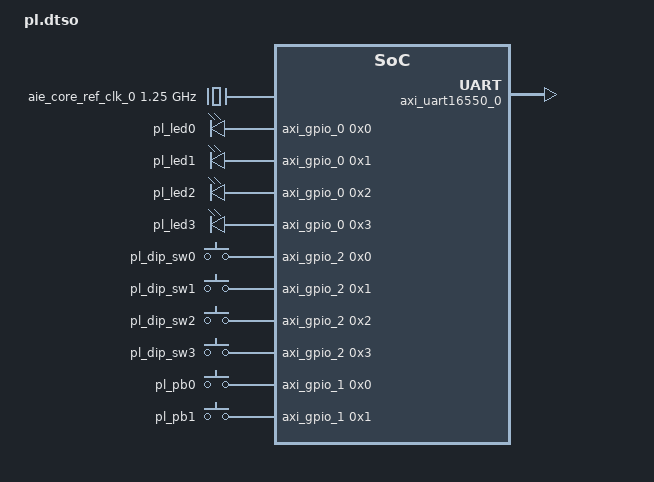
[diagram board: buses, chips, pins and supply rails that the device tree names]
/dts-v1/;
/plugin/;

&fpga {
        firmware-name = "vek280_base_pld.pdi";

        misc_clk_0: misc_clk_0 {
                #clock-cells = <0x0>;
                clock-frequency = <0x5f5e100>;
                compatible = "fixed-clock";
        };
};

&amba {

        axi_gpio_0: gpio@a6010000 {
                gpio-line-names = "pl_led0", "pl_led1", "pl_led2", "pl_led3";
                xlnx,all-inputs = <0x0>;
                xlnx,name = "axi_gpio_0";
                xlnx,tri-default = <0xffffffff>;
                xlnx,use-board-flow;
                clock-names = "s_axi_aclk";
                xlnx,gpio2-width = <0x20>;
                xlnx,dout-default-2 = <0x0>;
                xlnx,edk-iptype = "PERIPHERAL";
                xlnx,gpio2-board-interface = "Custom";
                xlnx,interrupt-present = <0x0>;
                device_type = "gpio";
                gpio-controller;
                xlnx,all-outputs-2 = <0x0>;
                clocks = <&misc_clk_0>;
                xlnx,all-inputs-2 = <0x0>;
                reg = <0x0 0xa6010000 0x0 0x10000>;
                xlnx,tri-default-2 = <0xffffffff>;
                xlnx,ip-name = "axi_gpio";
                xlnx,is-dual = <0x0>;
                xlnx,dout-default = <0x0>;
                xlnx,gpio-width = <0x4>;
                #gpio-cells = <0x2>;
                xlnx,all-outputs = <0x1>;
                compatible = "xlnx,axi-gpio-2.0", "xlnx,xps-gpio-1.00.a";
                xlnx,gpio-board-interface = "gpio_led";
        };

        axi_gpio_1: gpio@a6020000 {
                gpio-line-names = "pl_pb0", "pl_pb1";
                xlnx,all-inputs = <0x1>;
                xlnx,name = "axi_gpio_1";
                xlnx,tri-default = <0xffffffff>;
                xlnx,use-board-flow;
                clock-names = "s_axi_aclk";
                xlnx,gpio2-width = <0x20>;
                xlnx,dout-default-2 = <0x0>;
                xlnx,edk-iptype = "PERIPHERAL";
                xlnx,gpio2-board-interface = "Custom";
                xlnx,interrupt-present = <0x0>;
                device_type = "gpio";
                gpio-controller;
                xlnx,all-outputs-2 = <0x0>;
                clocks = <&misc_clk_0>;
                xlnx,all-inputs-2 = <0x0>;
                reg = <0x0 0xa6020000 0x0 0x10000>;
                xlnx,tri-default-2 = <0xffffffff>;
                xlnx,ip-name = "axi_gpio";
                xlnx,is-dual = <0x0>;
                xlnx,dout-default = <0x0>;
                xlnx,gpio-width = <0x2>;
                #gpio-cells = <0x2>;
                xlnx,all-outputs = <0x0>;
                compatible = "xlnx,axi-gpio-2.0", "xlnx,xps-gpio-1.00.a";
                xlnx,gpio-board-interface = "gpio_pb";
        };

        axi_gpio_2: gpio@a6030000 {
                gpio-line-names = "pl_dip_sw0", "pl_dip_sw1", "pl_dip_sw2", "pl_dip_sw3";
                xlnx,all-inputs = <0x1>;
                xlnx,name = "axi_gpio_2";
                xlnx,tri-default = <0xffffffff>;
                xlnx,use-board-flow;
                clock-names = "s_axi_aclk";
                xlnx,gpio2-width = <0x20>;
                xlnx,dout-default-2 = <0x0>;
                xlnx,edk-iptype = "PERIPHERAL";
                xlnx,gpio2-board-interface = "Custom";
                xlnx,interrupt-present = <0x0>;
                device_type = "gpio";
                gpio-controller;
                xlnx,all-outputs-2 = <0x0>;
                clocks = <&misc_clk_0>;
                xlnx,all-inputs-2 = <0x0>;
                reg = <0x0 0xa6030000 0x0 0x10000>;
                xlnx,tri-default-2 = <0xffffffff>;
                xlnx,ip-name = "axi_gpio";
                xlnx,is-dual = <0x0>;
                xlnx,dout-default = <0x0>;
                xlnx,gpio-width = <0x4>;
                #gpio-cells = <0x2>;
                xlnx,all-outputs = <0x0>;
                compatible = "xlnx,axi-gpio-2.0", "xlnx,xps-gpio-1.00.a";
                xlnx,gpio-board-interface = "gpio_dp";
        };

        ai_engine_0: ai_engine@20000000000 {
                xlnx,aie-site = "AIE_ML";
                xlnx,name = "ai_engine_0";
                xlnx,start-column = <0x0>;
                xlnx,name-si-axi = "S00_AXI";
                xlnx,shim-rows = /bits/ 8 <0x00 0x01>;
                xlnx,core-rows = /bits/ 8 <0x03 0x08>;
                xlnx,num-trig-out = <0x0>;
                xlnx,en-ext-rst = <0x0>;
                xlnx,nsu-dict = "NOC_NSU128_X1Y6 0x20000000000 NOC_NSU128_X2Y6 0x20002000000 NOC_NSU128_X3Y6 0x20008000000 NOC_NSU128_X4Y6 0x2000A000000 NOC_NSU128_X5Y6 0x20018000000 NOC_NSU128_X6Y6 0x20020000000 NOC_NSU128_X7Y6 0x2002C000000 NOC_NSU128_X8Y6 0x20032000000 NOC_NSU128_X9Y6 0x2003E000000 NOC_NSU128_X10Y6 0x20042000000 NOC_NSU128_X11Y6 0x20046000000 NOC_NSU128_X12Y6 0x2004A000000";
                xlnx,num-trig-in = <0x0>;
                power-domains = <&versal_firmware 0x18800000>;
                clock-names = "aclk0";
                xlnx,available-nsu = "NOC_NSU128_X1Y6 0x20000000000 NOC_NSU128_X2Y6 0x20002000000 NOC_NSU128_X3Y6 0x20008000000 NOC_NSU128_X4Y6 0x2000A000000 NOC_NSU128_X5Y6 0x20018000000 NOC_NSU128_X6Y6 0x20020000000 NOC_NSU128_X7Y6 0x2002C000000 NOC_NSU128_X8Y6 0x20032000000 NOC_NSU128_X9Y6 0x2003E000000 NOC_NSU128_X10Y6 0x20042000000 NOC_NSU128_X11Y6 0x20046000000 NOC_NSU128_X12Y6 0x2004A000000";
                xlnx,selected-nsu = <0x0>;
                xlnx,edk-iptype = "PERIPHERAL";
                xlnx,fast-dm-write;
                xlnx,name-si-axis = "S00_AXIS";
                xlnx,clk-names = "aclk0";
                xlnx,aie-core-ref-ctrl-freqmhz = <0x4e2>;
                xlnx,num-column = <0x1>;
                xlnx,name-mi-axi = "M00_AXI";
                xlnx,num-si-axis = <0x0>;
                #address-cells = <0x2>;
                xlnx,partition-enabled = <0x0>;
                xlnx,num-clks = <0x0>;
                ranges;
                xlnx,num-noc-axis-clks = <0x0>;
                clocks = <&aie_core_ref_clk_0>;
                reg = <0x200 0x0 0x1 0x0>;
                xlnx,fast-pm-write;
                xlnx,num-si-axi = <0x1>;
                #size-cells = <0x2>;
                xlnx,ip-name = "ai_engine";
                xlnx,mi-destid-pins;
                xlnx,mem-rows = /bits/ 8 <0x01 0x02>;
                xlnx,name-mi-axis = "M00_AXIS";
                xlnx,aie-gen = [02];
                xlnx,aie-max-freq = <0x4e2>;
                xlnx,en-addr-virtualization = <0x0>;
                xlnx,num-mi-axis = <0x0>;
                xlnx,aie-col-dict = "col00 0x20000000000 col01 0x20002000000 col02 0x20004000000 col03 0x20006000000 col04 0x20008000000 col05 0x2000A000000 col06 0x2000C000000 col07 0x2000E000000 col08 0x20010000000 col09 0x20012000000 col10 0x20014000000 col11 0x20016000000 col12 0x20018000000 col13 0x2001A000000 col14 0x2001C000000 col15 0x2001E000000 col16 0x20020000000 col17 0x20022000000 col18 0x20024000000 col19 0x20026000000 col20 0x20028000000 col21 0x2002A000000 col22 0x2002C000000 col23 0x2002E000000 col24 0x20030000000 col25 0x20032000000 col26 0x20034000000 col27 0x20036000000 col28 0x20038000000 col29 0x2003A000000 col30 0x2003C000000 col31 0x2003E000000 col32 0x20040000000 col33 0x20042000000 col34 0x20044000000 col35 0x20046000000 col36 0x20048000000 col37 0x2004A000000";
                xlnx,aie-ref-clk-freqmhz = <0x1fc9f08>;
                compatible = "xlnx,ai-engine-2.0", "xlnx,ai-engine-v2.0";
                xlnx,num-mi-axi = <0x0>;

                aie_aperture_0: aie_aperture@20000000000 {
                        xlnx,columns = <0x0 0x26>;
                        reg = <0x200 0x0 0x1 0x0>;
                        interrupt-names = "interrupt1", "interrupt2", "interrupt3";
                        #size-cells = <0x2>;
                        xlnx,node-id = <0x18800000>;
                        power-domains = <&versal_firmware 0x18800000>;
                        #address-cells = <0x2>;
                        interrupts = <0x0 0x94 0x4 0x0 0x95 0x4 0x0 0x96 0x4>;
                        interrupt-parent = <&gic>;
                        xlnx,device-name = <0x0>;
                };
        };

        axi_bram_ctrl_0: axi_bram_ctrl_0@a4000000 {
                xlnx,name = "axi_bram_ctrl_0";
                xlnx,s-axi-id-width = <0x1>;
                xlnx,mem-depth = <0x800>;
                xlnx,s-axi-ctrl-data-width = <0x20>;
                xlnx,bram-inst-mode = "EXTERNAL";
                xlnx,bram-addr-width = <0xb>;
                xlnx,data-width = <0x20>;
                clock-names = "s_axi_aclk";
                xlnx,edk-iptype = "PERIPHERAL";
                xlnx,ecc = <0x0>;
                xlnx,single-port-bram = <0x0>;
                xlnx,supports-narrow-burst = <0x0>;
                xlnx,s-axi-supports-narrow-burst = <0x0>;
                xlnx,id-width = <0x0>;
                xlnx,read-latency = <0x1>;
                xlnx,s-axi-ctrl-addr-width = <0x20>;
                clocks = <&misc_clk_0>;
                xlnx,bmg-instance = "EXTERNAL";
                reg = <0x0 0xa4000000 0x0 0x2000>;
                xlnx,ip-name = "axi_bram_ctrl";
                xlnx,fault-inject = <0x0>;
                xlnx,use-ecc = <0x0>;
                xlnx,memory-depth = <0x800>;
                xlnx,rd-cmd-optimization = <0x0>;
                xlnx,ecc-type = <0x0>;
                xlnx,ecc-onoff-reset-value = <0x0>;
                compatible = "xlnx,axi-bram-ctrl-4.1", "xlnx,axi-bram-ctrl";
                xlnx,edk-special = "BRAM_CTRL";
                xlnx,protocol = "AXI4";
        };

        axi_uart16550_0: serial@a6000000 {
                xlnx,name = "axi_uart16550_0";
                xlnx,is-a-16550 = <0x1>;
                xlnx,base-user = <0x1>;
                xlnx,use-board-flow;
                clock-names = "s_axi_aclk";
                xlnx,clock-freq = <0x5f5e100>;
                xlnx,external-xin-clk-hz-d = <0x19>;
                xlnx,edk-iptype = "PERIPHERAL";
                device_type = "serial";
                xlnx,use-modem-ports = <0x1>;
                clocks = <&misc_clk_0>;
                xlnx,has-external-xin = <0x0>;
                reg = <0x0 0xa6000000 0x0 0x10000>;
                xlnx,ip-name = "axi_uart16550";
                xlnx,uart-board-interface = "sysctrl_uart";
                xlnx,sim-device = "VERSAL_AI_EDGE";
                xlnx,use-user-ports = <0x1>;
                xlnx,s-axi-aclk-freq-hz-d = <0x64>;
                xlnx,has-external-rclk = <0x0>;
                xlnx,external-xin-clk-hz = <0x17d7840>;
                compatible = "xlnx,axi-uart16550-2.0", "xlnx,axi-uart16550";
        };

        aie_core_ref_clk_0: aie_core_ref_clk_0 {
                #clock-cells = <0x0>;
                clock-frequency = <0x4a817c80>;
                compatible = "fixed-clock";
        };

        zyxclmm_drm {
                compatible = "xlnx,zocl-versal";
                interrupt-parent = <&gic>;
                interrupts = <0x0 0x89 0x4 0x0 0x90 0x4 0x0 0x91 0x4 0x0 0x92 0x4 0x0 0x93 0x4 0x0 0x94 0x4 0x0 0x95 0x4 0x0 0x96 0x4>;
        };

        leds {
                compatible = "gpio-leds";

                pl_led0: led-0 {
                        default-state = "off";
                        gpios = <&axi_gpio_0 0x0 0x0>;
                        label = "pl_led0";
                };

                pl_led1: led-1 {
                        default-state = "off";
                        gpios = <&axi_gpio_0 0x1 0x0>;
                        label = "pl_led1";
                };

                pl_led2: led-2 {
                        default-state = "off";
                        gpios = <&axi_gpio_0 0x2 0x0>;
                        label = "pl_led2";
                };

                pl_led3: led-3 {
                        default-state = "off";
                        gpios = <&axi_gpio_0 0x3 0x0>;
                        label = "pl_led3";
                };
        };

        pl_gpio_keys: gpio-keys {
                poll-interval = <0x64>;
                label = "pl-gpio-keys";
                compatible = "gpio-keys-polled";

                pl_dip_sw0 {
                        linux,code = <0x100>;
                        gpios = <&axi_gpio_2 0x0 0x0>;
                        label = "pl_dip_sw0";
                };

                pl_dip_sw1 {
                        linux,code = <0x101>;
                        gpios = <&axi_gpio_2 0x1 0x0>;
                        label = "pl_dip_sw1";
                };

                pl_dip_sw2 {
                        linux,code = <0x102>;
                        gpios = <&axi_gpio_2 0x2 0x0>;
                        label = "pl_dip_sw2";
                };

                pl_dip_sw3 {
                        linux,code = <0x103>;
                        gpios = <&axi_gpio_2 0x3 0x0>;
                        label = "pl_dip_sw3";
                };

                pl_pb0 {
                        debounce-interval = <0xa>;
                        linux,code = <0x104>;
                        gpios = <&axi_gpio_1 0x0 0x0>;
                        label = "pl_pb0";
                };

                pl_pb1 {
                        debounce-interval = <0xa>;
                        linux,code = <0x105>;
                        gpios = <&axi_gpio_1 0x1 0x0>;
                        label = "pl_pb1";
                };
        };
};

&cpus_a72 {
        address-map = <0x0 0xf0000000 0x1 0x0 0xf0000000 0x0 0x10000000 0x0 0xf9000000 0x2 0x0 0xf9000000 0x0 0x80000 0x0 0xa4000000 0x3 0x0 0xa4000000 0x0 0x2000 0x0 0xa4000000 0x4 0x0 0xa4000000 0x0 0x2000 0x0 0x0 0x5 0x0 0x0 0x0 0x80000000 0x8 0x0 0x5 0x8 0x0 0x0 0x80000000 0x500 0x0 0x6 0x500 0x0 0x1 0x0 0x600 0x0 0x7 0x600 0x0 0x1 0x0 0x0 0xf9020000 0x8 0x0 0xf9020000 0x0 0x20000 0x0 0xff330000 0x9 0x0 0xff330000 0x0 0x10000 0x0 0xff360000 0xa 0x0 0xff360000 0x0 0x10000 0x0 0xff370000 0xb 0x0 0xff370000 0x0 0x10000 0x0 0xff380000 0xc 0x0 0xff380000 0x0 0x10000 0x0 0xff3a0000 0xd 0x0 0xff3a0000 0x0 0x10000 0x0 0xfffc0000 0xe 0x0 0xfffc0000 0x0 0x40000 0x0 0xa6000000 0xf 0x0 0xa6000000 0x0 0x10000 0x0 0xa6010000 0x10 0x0 0xa6010000 0x0 0x10000 0x0 0xa6020000 0x11 0x0 0xa6020000 0x0 0x10000 0x0 0xa6030000 0x12 0x0 0xa6030000 0x0 0x10000 0x0 0xf0310000 0x13 0x0 0xf0310000 0x0 0x8000 0x0 0xf0800000 0x14 0x0 0xf0800000 0x0 0x10000 0x0 0xf08d0000 0x15 0x0 0xf08d0000 0x0 0x10000 0x0 0xf0980000 0x16 0x0 0xf0980000 0x0 0x10000 0x0 0xf09d0000 0x17 0x0 0xf09d0000 0x0 0x10000 0x0 0xf0a10000 0x18 0x0 0xf0a10000 0x0 0x10000 0x0 0xf0a50000 0x19 0x0 0xf0a50000 0x0 0x10000 0x0 0xf0b70000 0x1a 0x0 0xf0b70000 0x0 0x10000 0x0 0xf0b80000 0x1b 0x0 0xf0b80000 0x0 0x10000 0x0 0xf0bb0000 0x1c 0x0 0xf0bb0000 0x0 0x10000 0x0 0xf0bc0000 0x1d 0x0 0xf0bc0000 0x0 0x10000 0x0 0xf0bd0000 0x1e 0x0 0xf0bd0000 0x0 0x10000 0x0 0xf0c20000 0x1f 0x0 0xf0c20000 0x0 0x10000 0x0 0xf0c30000 0x20 0x0 0xf0c30000 0x0 0x10000 0x0 0xf0c60000 0x21 0x0 0xf0c60000 0x0 0x10000 0x0 0xf0ca0000 0x22 0x0 0xf0ca0000 0x0 0x10000 0x0 0xf0d00000 0x23 0x0 0xf0d00000 0x0 0x10000 0x0 0xf0d10000 0x24 0x0 0xf0d10000 0x0 0x10000 0x0 0xf0d20000 0x25 0x0 0xf0d20000 0x0 0x10000 0x0 0xf0d30000 0x26 0x0 0xf0d30000 0x0 0x10000 0x0 0xf0d40000 0x27 0x0 0xf0d40000 0x0 0x10000 0x0 0xf0d50000 0x28 0x0 0xf0d50000 0x0 0x10000 0x0 0xf0d60000 0x29 0x0 0xf0d60000 0x0 0x10000 0x0 0xf0d70000 0x2a 0x0 0xf0d70000 0x0 0x10000 0x0 0xf0f00000 0x2b 0x0 0xf0f00000 0x0 0x10000 0x0 0xf0f20000 0x2c 0x0 0xf0f20000 0x0 0x10000 0x0 0xf0f40000 0x2d 0x0 0xf0f40000 0x0 0x10000 0x0 0xf0f50000 0x2e 0x0 0xf0f50000 0x0 0x10000 0x0 0xf0f60000 0x2f 0x0 0xf0f60000 0x0 0x10000 0x0 0xf0f70000 0x30 0x0 0xf0f70000 0x0 0x10000 0x0 0xf0f80000 0x31 0x0 0xf0f80000 0x0 0x10000 0x0 0xf0fa0000 0x32 0x0 0xf0fa0000 0x0 0x10000 0x0 0xf0fd0000 0x33 0x0 0xf0fd0000 0x0 0x10000 0x0 0xf1010000 0x34 0x0 0xf1010000 0x0 0x10000 0x0 0xf1020000 0x35 0x0 0xf1020000 0x0 0x10000 0x0 0xf1050000 0x36 0x0 0xf1050000 0x0 0x10000 0x0 0xf1060000 0x37 0x0 0xf1060000 0x0 0x10000 0x0 0xf1110000 0x38 0x0 0xf1110000 0x0 0x50000 0x0 0xf1160000 0x39 0x0 0xf1160000 0x0 0x30000 0x0 0xf11a0000 0x3a 0x0 0xf11a0000 0x0 0x20000 0x0 0xf11c0000 0x3b 0x0 0xf11c0000 0x0 0x10000 0x0 0xf11d0000 0x3c 0x0 0xf11d0000 0x0 0x10000 0x0 0xf11e0000 0x3d 0x0 0xf11e0000 0x0 0x10000 0x0 0xf11f0000 0x3e 0x0 0xf11f0000 0x0 0x10000 0x0 0xf1200000 0x3f 0x0 0xf1200000 0x0 0x10000 0x0 0xf1210000 0x40 0x0 0xf1210000 0x0 0x10000 0x0 0xf1220000 0x41 0x0 0xf1220000 0x0 0x10000 0x0 0xf1230000 0x42 0x0 0xf1230000 0x0 0x10000 0x0 0xf1240000 0x43 0x0 0xf1240000 0x0 0x10000 0x0 0xf1250000 0x44 0x0 0xf1250000 0x0 0x10000 0x0 0xf1260000 0x45 0x0 0xf1260000 0x0 0x10000 0x0 0xf1270000 0x46 0x0 0xf1270000 0x0 0x30000 0x0 0xf12a0000 0x47 0x0 0xf12a0000 0x0 0x10000 0x0 0xf12b0000 0x48 0x0 0xf12b0000 0x0 0x10000 0x0 0xf12d0000 0x49 0x0 0xf12d0000 0x0 0x1000 0x0 0xf12d2000 0x4a 0x0 0xf12d2000 0x0 0x1000 0x0 0xf12d4000 0x4b 0x0 0xf12d4000 0x0 0x1000 0x0 0xf12d6000 0x4c 0x0 0xf12d6000 0x0 0x1000 0x0 0xf12d8000 0x4d 0x0 0xf12d8000 0x0 0x1000 0x0 0xf12da000 0x4e 0x0 0xf12da000 0x0 0x1000 0x0 0xf12dc000 0x4f 0x0 0xf12dc000 0x0 0x1000 0x0 0xf12de000 0x50 0x0 0xf12de000 0x0 0x1000 0x0 0xf12e0000 0x51 0x0 0xf12e0000 0x0 0x1000 0x0 0xf12e2000 0x52 0x0 0xf12e2000 0x0 0x1000 0x0 0xf12e4000 0x53 0x0 0xf12e4000 0x0 0x1000 0x0 0xf12e6000 0x54 0x0 0xf12e6000 0x0 0x1000 0x0 0xf12e8000 0x55 0x0 0xf12e8000 0x0 0x1000 0x0 0xf12ea000 0x56 0x0 0xf12ea000 0x0 0x1000 0x0 0xf12ec000 0x57 0x0 0xf12ec000 0x0 0x1000 0x0 0xf12ee000 0x58 0x0 0xf12ee000 0x0 0x1000 0x0 0xf12f0000 0x59 0x0 0xf12f0000 0x0 0x10000 0x0 0xf1300000 0x5a 0x0 0xf1300000 0x0 0x10000 0x0 0xf1310000 0x5b 0x0 0xf1310000 0x0 0x10000 0x0 0xf2100000 0x5c 0x0 0xf2100000 0x0 0x10000 0x0 0xf6000000 0x5d 0x0 0xf6000000 0x0 0x2000000 0x0 0xf9000000 0x5e 0x0 0xf9000000 0x0 0x70000 0x0 0x0 0x5f 0x0 0x0 0x0 0xfd000000 0x0 0xfd000000 0x60 0x0 0xfd000000 0x0 0x100000 0x0 0xfd1a0000 0x61 0x0 0xfd1a0000 0x0 0x140000 0x0 0xfd360000 0x62 0x0 0xfd360000 0x0 0x10000 0x0 0xfd380000 0x63 0x0 0xfd380000 0x0 0x10000 0x0 0xfd390000 0x64 0x0 0xfd390000 0x0 0x10000 0x0 0xfd5c0000 0x65 0x0 0xfd5c0000 0x0 0x10000 0x0 0xfd5e0000 0x66 0x0 0xfd5e0000 0x0 0x10000 0x0 0xfd5f0000 0x67 0x0 0xfd5f0000 0x0 0x10000 0x0 0xfd610000 0x68 0x0 0xfd610000 0x0 0x10000 0x0 0xfd690000 0x69 0x0 0xfd690000 0x0 0x10000 0x0 0xfd700000 0x6a 0x0 0xfd700000 0x0 0x100000 0x0 0xfd800000 0x6b 0x0 0xfd800000 0x0 0x800000 0x0 0xfe200000 0x6c 0x0 0xfe200000 0x0 0x100000 0x0 0xff000000 0x6d 0x0 0xff000000 0x0 0x10000 0x0 0xff020000 0x6e 0x0 0xff020000 0x0 0x10000 0x0 0xff030000 0x6f 0x0 0xff030000 0x0 0x10000 0x0 0xff060000 0x70 0x0 0xff060000 0x0 0x10000 0x0 0xff070000 0x71 0x0 0xff070000 0x0 0x10000 0x0 0xff080000 0x72 0x0 0xff080000 0x0 0x20000 0x0 0xff0a0000 0x73 0x0 0xff0a0000 0x0 0x10000 0x0 0xff0c0000 0x74 0x0 0xff0c0000 0x0 0x10000 0x0 0xff0e0000 0x75 0x0 0xff0e0000 0x0 0x10000 0x0 0xff0f0000 0x76 0x0 0xff0f0000 0x0 0x10000 0x0 0xff100000 0x77 0x0 0xff100000 0x0 0x10000 0x0 0xff110000 0x78 0x0 0xff110000 0x0 0x10000 0x0 0xff130000 0x79 0x0 0xff130000 0x0 0x10000 0x0 0xff140000 0x7a 0x0 0xff140000 0x0 0x10000 0x0 0xff410000 0x7b 0x0 0xff410000 0x0 0x100000 0x0 0xff510000 0x7c 0x0 0xff510000 0x0 0x40000 0x0 0xff5e0000 0x7d 0x0 0xff5e0000 0x0 0x300000 0x0 0xff960000 0x7e 0x0 0xff960000 0x0 0x10000 0x0 0xff980000 0x7f 0x0 0xff980000 0x0 0x10000 0x0 0xff990000 0x80 0x0 0xff990000 0x0 0x10000 0x0 0xff9a0000 0x81 0x0 0xff9a0000 0x0 0x10000 0x0 0xff9b0000 0x82 0x0 0xff9b0000 0x0 0x10000 0x0 0xff9d0000 0x83 0x0 0xff9d0000 0x0 0x10000 0x0 0xffa80000 0x84 0x0 0xffa80000 0x0 0x10000 0x0 0xffa90000 0x85 0x0 0xffa90000 0x0 0x10000 0x0 0xffaa0000 0x86 0x0 0xffaa0000 0x0 0x10000 0x0 0xffab0000 0x87 0x0 0xffab0000 0x0 0x10000 0x0 0xffac0000 0x88 0x0 0xffac0000 0x0 0x10000 0x0 0xffad0000 0x89 0x0 0xffad0000 0x0 0x10000 0x0 0xffae0000 0x8a 0x0 0xffae0000 0x0 0x10000 0x0 0xffaf0000 0x8b 0x0 0xffaf0000 0x0 0x10000 0x0 0xffc90000 0x8c 0x0 0xffc90000 0x0 0xf000 0x0 0xffe00000 0x8d 0x0 0xffe00000 0x0 0x40000 0x0 0xffe90000 0x8e 0x0 0xffe90000 0x0 0x10000 0x0 0xffeb0000 0x8f 0x0 0xffeb0000 0x0 0x10000 0x200 0x0 0x90 0x200 0x0 0x1 0x0>;
};

&cpus_microblaze_1 {
        address-map = <0xf0000000 0x1 0xf0000000 0x10000000 0xa4000000 0x3 0xa4000000 0x2000 0xa4000000 0x4 0xa4000000 0x2000 0x0 0x5 0x0 0x80000000 0xff310000 0x99 0xff310000 0x10000 0xfffc0000 0xe 0xfffc0000 0x40000 0xa6000000 0xf 0xa6000000 0x10000 0xa6010000 0x10 0xa6010000 0x10000 0xa6020000 0x11 0xa6020000 0x10000 0xa6030000 0x12 0xa6030000 0x10000 0xf0310000 0x13 0xf0310000 0x8000 0xf1010000 0x34 0xf1010000 0x10000 0xf1020000 0x35 0xf1020000 0x10000 0xf1050000 0x36 0xf1050000 0x10000 0xf1060000 0x37 0xf1060000 0x10000 0xf1110000 0x38 0xf1110000 0x50000 0xf1160000 0x39 0xf1160000 0x30000 0xf11a0000 0x3a 0xf11a0000 0x20000 0xf11c0000 0x3b 0xf11c0000 0x10000 0xf11d0000 0x3c 0xf11d0000 0x10000 0xf11e0000 0x3d 0xf11e0000 0x10000 0xf11f0000 0x3e 0xf11f0000 0x10000 0xf1200000 0x3f 0xf1200000 0x10000 0xf1210000 0x40 0xf1210000 0x10000 0xf1220000 0x41 0xf1220000 0x10000 0xf1230000 0x42 0xf1230000 0x10000 0xf1240000 0x43 0xf1240000 0x10000 0xf1250000 0x44 0xf1250000 0x10000 0xf1260000 0x45 0xf1260000 0x10000 0xf1270000 0x46 0xf1270000 0x30000 0xf12a0000 0x47 0xf12a0000 0x10000 0xf12b0000 0x48 0xf12b0000 0x10000 0xf12d0000 0x49 0xf12d0000 0x1000 0xf12d2000 0x4a 0xf12d2000 0x1000 0xf12d4000 0x4b 0xf12d4000 0x1000 0xf12d6000 0x4c 0xf12d6000 0x1000 0xf12d8000 0x4d 0xf12d8000 0x1000 0xf12da000 0x4e 0xf12da000 0x1000 0xf12dc000 0x4f 0xf12dc000 0x1000 0xf12de000 0x50 0xf12de000 0x1000 0xf12e0000 0x51 0xf12e0000 0x1000 0xf12e2000 0x52 0xf12e2000 0x1000 0xf12e4000 0x53 0xf12e4000 0x1000 0xf12e6000 0x54 0xf12e6000 0x1000 0xf12e8000 0x55 0xf12e8000 0x1000 0xf12ea000 0x56 0xf12ea000 0x1000 0xf12ec000 0x57 0xf12ec000 0x1000 0xf12ee000 0x58 0xf12ee000 0x1000 0xf12f0000 0x59 0xf12f0000 0x10000 0xf1300000 0x5a 0xf1300000 0x10000 0xf1310000 0x5b 0xf1310000 0x10000 0xf2100000 0x5c 0xf2100000 0x10000 0xf6000000 0x5d 0xf6000000 0x2000000 0xfd000000 0x60 0xfd000000 0x100000 0xfd1a0000 0x61 0xfd1a0000 0x140000 0xfd360000 0x62 0xfd360000 0x10000 0xfd380000 0x63 0xfd380000 0x10000 0xfd390000 0x64 0xfd390000 0x10000 0xfd5e0000 0x66 0xfd5e0000 0x10000 0xfd5f0000 0x67 0xfd5f0000 0x10000 0xfd610000 0x68 0xfd610000 0x10000 0xfd690000 0x69 0xfd690000 0x10000 0xfd700000 0x6a 0xfd700000 0x100000 0xfd800000 0x6b 0xfd800000 0x800000 0xfe200000 0x6c 0xfe200000 0x100000 0xff000000 0x6d 0xff000000 0x10000 0xff020000 0x6e 0xff020000 0x10000 0xff030000 0x6f 0xff030000 0x10000 0xff060000 0x70 0xff060000 0x10000 0xff070000 0x71 0xff070000 0x10000 0xff080000 0x72 0xff080000 0x20000 0xff0a0000 0x73 0xff0a0000 0x10000 0xff0c0000 0x74 0xff0c0000 0x10000 0xff0e0000 0x75 0xff0e0000 0x10000 0xff0f0000 0x76 0xff0f0000 0x10000 0xff100000 0x77 0xff100000 0x10000 0xff110000 0x78 0xff110000 0x10000 0xff130000 0x79 0xff130000 0x10000 0xff140000 0x7a 0xff140000 0x10000 0xff410000 0x7b 0xff410000 0x100000 0xff510000 0x7c 0xff510000 0x40000 0xff5e0000 0x7d 0xff5e0000 0x300000 0xff960000 0x7e 0xff960000 0x10000 0xff980000 0x7f 0xff980000 0x10000 0xff990000 0x80 0xff990000 0x10000 0xff9b0000 0x82 0xff9b0000 0x10000 0xff9d0000 0x83 0xff9d0000 0x10000 0xffa80000 0x84 0xffa80000 0x10000 0xffa90000 0x85 0xffa90000 0x10000 0xffaa0000 0x86 0xffaa0000 0x10000 0xffab0000 0x87 0xffab0000 0x10000 0xffac0000 0x88 0xffac0000 0x10000 0xffad0000 0x89 0xffad0000 0x10000 0xffae0000 0x8a 0xffae0000 0x10000 0xffaf0000 0x8b 0xffaf0000 0x10000 0xffc90000 0x8c 0xffc90000 0xf000 0xffe00000 0x8d 0xffe00000 0x40000 0xffe90000 0x8e 0xffe90000 0x10000 0xffeb0000 0x8f 0xffeb0000 0x10000 0xffc00000 0x9a 0xffc00000 0x20000 0xffc20000 0x9b 0xffc20000 0x20000 0xffc80000 0x9c 0xffc80000 0x8000 0xffcc0000 0x9d 0xffcc0000 0x10000 0xffcd0000 0x9e 0xffcd0000 0x10000>;
};

&cpus_r5_0 {
        address-map = <0xf0000000 0x1 0xf0000000 0x10000000 0xf9000000 0x9f 0xf9000000 0x3000 0xa4000000 0x3 0xa4000000 0x2000 0xa4000000 0x4 0xa4000000 0x2000 0x40000 0x5 0x40000 0x7ffc0000 0xff340000 0xa0 0xff340000 0x10000 0xfffc0000 0xe 0xfffc0000 0x40000 0xa6000000 0xf 0xa6000000 0x10000 0xa6010000 0x10 0xa6010000 0x10000 0xa6020000 0x11 0xa6020000 0x10000 0xa6030000 0x12 0xa6030000 0x10000 0xf0310000 0x13 0xf0310000 0x8000 0xf0800000 0x14 0xf0800000 0x10000 0xf08d0000 0x15 0xf08d0000 0x10000 0xf0980000 0x16 0xf0980000 0x10000 0xf09d0000 0x17 0xf09d0000 0x10000 0xf0a10000 0x18 0xf0a10000 0x10000 0xf0a50000 0x19 0xf0a50000 0x10000 0xf0b70000 0x1a 0xf0b70000 0x10000 0xf0b80000 0x1b 0xf0b80000 0x10000 0xf0bb0000 0x1c 0xf0bb0000 0x10000 0xf0bc0000 0x1d 0xf0bc0000 0x10000 0xf0bd0000 0x1e 0xf0bd0000 0x10000 0xf0c20000 0x1f 0xf0c20000 0x10000 0xf0c30000 0x20 0xf0c30000 0x10000 0xf0c60000 0x21 0xf0c60000 0x10000 0xf0ca0000 0x22 0xf0ca0000 0x10000 0xf0d00000 0x23 0xf0d00000 0x10000 0xf0d10000 0x24 0xf0d10000 0x10000 0xf0d20000 0x25 0xf0d20000 0x10000 0xf0d30000 0x26 0xf0d30000 0x10000 0xf0d40000 0x27 0xf0d40000 0x10000 0xf0d50000 0x28 0xf0d50000 0x10000 0xf0d60000 0x29 0xf0d60000 0x10000 0xf0d70000 0x2a 0xf0d70000 0x10000 0xf0f00000 0x2b 0xf0f00000 0x10000 0xf0f20000 0x2c 0xf0f20000 0x10000 0xf0f40000 0x2d 0xf0f40000 0x10000 0xf0f50000 0x2e 0xf0f50000 0x10000 0xf0f60000 0x2f 0xf0f60000 0x10000 0xf0f70000 0x30 0xf0f70000 0x10000 0xf0f80000 0x31 0xf0f80000 0x10000 0xf0fa0000 0x32 0xf0fa0000 0x10000 0xf0fd0000 0x33 0xf0fd0000 0x10000 0xf1010000 0x34 0xf1010000 0x10000 0xf1020000 0x35 0xf1020000 0x10000 0xf1050000 0x36 0xf1050000 0x10000 0xf1060000 0x37 0xf1060000 0x10000 0xf1110000 0x38 0xf1110000 0x50000 0xf1160000 0x39 0xf1160000 0x30000 0xf11a0000 0x3a 0xf11a0000 0x20000 0xf11c0000 0x3b 0xf11c0000 0x10000 0xf11d0000 0x3c 0xf11d0000 0x10000 0xf11e0000 0x3d 0xf11e0000 0x10000 0xf11f0000 0x3e 0xf11f0000 0x10000 0xf1200000 0x3f 0xf1200000 0x10000 0xf1210000 0x40 0xf1210000 0x10000 0xf1220000 0x41 0xf1220000 0x10000 0xf1230000 0x42 0xf1230000 0x10000 0xf1240000 0x43 0xf1240000 0x10000 0xf1250000 0x44 0xf1250000 0x10000 0xf1260000 0x45 0xf1260000 0x10000 0xf1270000 0x46 0xf1270000 0x30000 0xf12a0000 0x47 0xf12a0000 0x10000 0xf12b0000 0x48 0xf12b0000 0x10000 0xf12d0000 0x49 0xf12d0000 0x1000 0xf12d2000 0x4a 0xf12d2000 0x1000 0xf12d4000 0x4b 0xf12d4000 0x1000 0xf12d6000 0x4c 0xf12d6000 0x1000 0xf12d8000 0x4d 0xf12d8000 0x1000 0xf12da000 0x4e 0xf12da000 0x1000 0xf12dc000 0x4f 0xf12dc000 0x1000 0xf12de000 0x50 0xf12de000 0x1000 0xf12e0000 0x51 0xf12e0000 0x1000 0xf12e2000 0x52 0xf12e2000 0x1000 0xf12e4000 0x53 0xf12e4000 0x1000 0xf12e6000 0x54 0xf12e6000 0x1000 0xf12e8000 0x55 0xf12e8000 0x1000 0xf12ea000 0x56 0xf12ea000 0x1000 0xf12ec000 0x57 0xf12ec000 0x1000 0xf12ee000 0x58 0xf12ee000 0x1000 0xf12f0000 0x59 0xf12f0000 0x10000 0xf1300000 0x5a 0xf1300000 0x10000 0xf1310000 0x5b 0xf1310000 0x10000 0xf2100000 0x5c 0xf2100000 0x10000 0xf6000000 0x5d 0xf6000000 0x2000000 0xfd000000 0x60 0xfd000000 0x100000 0xfd1a0000 0x61 0xfd1a0000 0x140000 0xfd360000 0x62 0xfd360000 0x10000 0xfd380000 0x63 0xfd380000 0x10000 0xfd390000 0x64 0xfd390000 0x10000 0xfd5c0000 0x65 0xfd5c0000 0x10000 0xfd5e0000 0x66 0xfd5e0000 0x10000 0xfd5f0000 0x67 0xfd5f0000 0x10000 0xfd610000 0x68 0xfd610000 0x10000 0xfd690000 0x69 0xfd690000 0x10000 0xfd700000 0x6a 0xfd700000 0x100000 0xfd800000 0x6b 0xfd800000 0x800000 0xfe200000 0x6c 0xfe200000 0x100000 0xff000000 0x6d 0xff000000 0x10000 0xff020000 0x6e 0xff020000 0x10000 0xff030000 0x6f 0xff030000 0x10000 0xff060000 0x70 0xff060000 0x10000 0xff070000 0x71 0xff070000 0x10000 0xff080000 0x72 0xff080000 0x20000 0xff0a0000 0x73 0xff0a0000 0x10000 0xff0c0000 0x74 0xff0c0000 0x10000 0xff0e0000 0x75 0xff0e0000 0x10000 0xff0f0000 0x76 0xff0f0000 0x10000 0xff100000 0x77 0xff100000 0x10000 0xff110000 0x78 0xff110000 0x10000 0xff130000 0x79 0xff130000 0x10000 0xff140000 0x7a 0xff140000 0x10000 0xff410000 0x7b 0xff410000 0x100000 0xff510000 0x7c 0xff510000 0x40000 0xff5e0000 0x7d 0xff5e0000 0x300000 0xff960000 0x7e 0xff960000 0x10000 0xff980000 0x7f 0xff980000 0x10000 0xff990000 0x80 0xff990000 0x10000 0xff9a0000 0x81 0xff9a0000 0x10000 0xff9b0000 0x82 0xff9b0000 0x10000 0xff9d0000 0x83 0xff9d0000 0x10000 0xffa80000 0x84 0xffa80000 0x10000 0xffa90000 0x85 0xffa90000 0x10000 0xffaa0000 0x86 0xffaa0000 0x10000 0xffab0000 0x87 0xffab0000 0x10000 0xffac0000 0x88 0xffac0000 0x10000 0xffad0000 0x89 0xffad0000 0x10000 0xffae0000 0x8a 0xffae0000 0x10000 0xffaf0000 0x8b 0xffaf0000 0x10000 0xffc90000 0x8c 0xffc90000 0xf000 0x0 0xa1 0x0 0x10000 0x0 0xa2 0x0 0x40000 0x20000 0xa3 0x20000 0x10000 0xf9000000 0xa4 0xf9000000 0x3000 0xffe40000 0xa5 0xffe40000 0x10000 0xffe50000 0xa6 0xffe50000 0x10000 0xffec0000 0xa7 0xffec0000 0x10000 0xffed0000 0xa8 0xffed0000 0x10000>;
};

&cpus_r5_1 {
        address-map = <0xf0000000 0x1 0xf0000000 0x10000000 0xf9000000 0x9f 0xf9000000 0x3000 0xa4000000 0x3 0xa4000000 0x2000 0xa4000000 0x4 0xa4000000 0x2000 0x40000 0x5 0x40000 0x7ffc0000 0xff350000 0xa9 0xff350000 0x10000 0xfffc0000 0xe 0xfffc0000 0x40000 0xa6000000 0xf 0xa6000000 0x10000 0xa6010000 0x10 0xa6010000 0x10000 0xa6020000 0x11 0xa6020000 0x10000 0xa6030000 0x12 0xa6030000 0x10000 0xf0310000 0x13 0xf0310000 0x8000 0xf0800000 0x14 0xf0800000 0x10000 0xf08d0000 0x15 0xf08d0000 0x10000 0xf0980000 0x16 0xf0980000 0x10000 0xf09d0000 0x17 0xf09d0000 0x10000 0xf0a10000 0x18 0xf0a10000 0x10000 0xf0a50000 0x19 0xf0a50000 0x10000 0xf0b70000 0x1a 0xf0b70000 0x10000 0xf0b80000 0x1b 0xf0b80000 0x10000 0xf0bb0000 0x1c 0xf0bb0000 0x10000 0xf0bc0000 0x1d 0xf0bc0000 0x10000 0xf0bd0000 0x1e 0xf0bd0000 0x10000 0xf0c20000 0x1f 0xf0c20000 0x10000 0xf0c30000 0x20 0xf0c30000 0x10000 0xf0c60000 0x21 0xf0c60000 0x10000 0xf0ca0000 0x22 0xf0ca0000 0x10000 0xf0d00000 0x23 0xf0d00000 0x10000 0xf0d10000 0x24 0xf0d10000 0x10000 0xf0d20000 0x25 0xf0d20000 0x10000 0xf0d30000 0x26 0xf0d30000 0x10000 0xf0d40000 0x27 0xf0d40000 0x10000 0xf0d50000 0x28 0xf0d50000 0x10000 0xf0d60000 0x29 0xf0d60000 0x10000 0xf0d70000 0x2a 0xf0d70000 0x10000 0xf0f00000 0x2b 0xf0f00000 0x10000 0xf0f20000 0x2c 0xf0f20000 0x10000 0xf0f40000 0x2d 0xf0f40000 0x10000 0xf0f50000 0x2e 0xf0f50000 0x10000 0xf0f60000 0x2f 0xf0f60000 0x10000 0xf0f70000 0x30 0xf0f70000 0x10000 0xf0f80000 0x31 0xf0f80000 0x10000 0xf0fa0000 0x32 0xf0fa0000 0x10000 0xf0fd0000 0x33 0xf0fd0000 0x10000 0xf1010000 0x34 0xf1010000 0x10000 0xf1020000 0x35 0xf1020000 0x10000 0xf1050000 0x36 0xf1050000 0x10000 0xf1060000 0x37 0xf1060000 0x10000 0xf1110000 0x38 0xf1110000 0x50000 0xf1160000 0x39 0xf1160000 0x30000 0xf11a0000 0x3a 0xf11a0000 0x20000 0xf11c0000 0x3b 0xf11c0000 0x10000 0xf11d0000 0x3c 0xf11d0000 0x10000 0xf11e0000 0x3d 0xf11e0000 0x10000 0xf11f0000 0x3e 0xf11f0000 0x10000 0xf1200000 0x3f 0xf1200000 0x10000 0xf1210000 0x40 0xf1210000 0x10000 0xf1220000 0x41 0xf1220000 0x10000 0xf1230000 0x42 0xf1230000 0x10000 0xf1240000 0x43 0xf1240000 0x10000 0xf1250000 0x44 0xf1250000 0x10000 0xf1260000 0x45 0xf1260000 0x10000 0xf1270000 0x46 0xf1270000 0x30000 0xf12a0000 0x47 0xf12a0000 0x10000 0xf12b0000 0x48 0xf12b0000 0x10000 0xf12d0000 0x49 0xf12d0000 0x1000 0xf12d2000 0x4a 0xf12d2000 0x1000 0xf12d4000 0x4b 0xf12d4000 0x1000 0xf12d6000 0x4c 0xf12d6000 0x1000 0xf12d8000 0x4d 0xf12d8000 0x1000 0xf12da000 0x4e 0xf12da000 0x1000 0xf12dc000 0x4f 0xf12dc000 0x1000 0xf12de000 0x50 0xf12de000 0x1000 0xf12e0000 0x51 0xf12e0000 0x1000 0xf12e2000 0x52 0xf12e2000 0x1000 0xf12e4000 0x53 0xf12e4000 0x1000 0xf12e6000 0x54 0xf12e6000 0x1000 0xf12e8000 0x55 0xf12e8000 0x1000 0xf12ea000 0x56 0xf12ea000 0x1000 0xf12ec000 0x57 0xf12ec000 0x1000 0xf12ee000 0x58 0xf12ee000 0x1000 0xf12f0000 0x59 0xf12f0000 0x10000 0xf1300000 0x5a 0xf1300000 0x10000 0xf1310000 0x5b 0xf1310000 0x10000 0xf2100000 0x5c 0xf2100000 0x10000 0xf6000000 0x5d 0xf6000000 0x2000000 0xfd000000 0x60 0xfd000000 0x100000 0xfd1a0000 0x61 0xfd1a0000 0x140000 0xfd360000 0x62 0xfd360000 0x10000 0xfd380000 0x63 0xfd380000 0x10000 0xfd390000 0x64 0xfd390000 0x10000 0xfd5c0000 0x65 0xfd5c0000 0x10000 0xfd5e0000 0x66 0xfd5e0000 0x10000 0xfd5f0000 0x67 0xfd5f0000 0x10000 0xfd610000 0x68 0xfd610000 0x10000 0xfd690000 0x69 0xfd690000 0x10000 0xfd700000 0x6a 0xfd700000 0x100000 0xfd800000 0x6b 0xfd800000 0x800000 0xfe200000 0x6c 0xfe200000 0x100000 0xff000000 0x6d 0xff000000 0x10000 0xff020000 0x6e 0xff020000 0x10000 0xff030000 0x6f 0xff030000 0x10000 0xff060000 0x70 0xff060000 0x10000 0xff070000 0x71 0xff070000 0x10000 0xff080000 0x72 0xff080000 0x20000 0xff0a0000 0x73 0xff0a0000 0x10000 0xff0c0000 0x74 0xff0c0000 0x10000 0xff0e0000 0x75 0xff0e0000 0x10000 0xff0f0000 0x76 0xff0f0000 0x10000 0xff100000 0x77 0xff100000 0x10000 0xff110000 0x78 0xff110000 0x10000 0xff130000 0x79 0xff130000 0x10000 0xff140000 0x7a 0xff140000 0x10000 0xff410000 0x7b 0xff410000 0x100000 0xff510000 0x7c 0xff510000 0x40000 0xff5e0000 0x7d 0xff5e0000 0x300000 0xff960000 0x7e 0xff960000 0x10000 0xff980000 0x7f 0xff980000 0x10000 0xff990000 0x80 0xff990000 0x10000 0xff9a0000 0x81 0xff9a0000 0x10000 0xff9b0000 0x82 0xff9b0000 0x10000 0xff9d0000 0x83 0xff9d0000 0x10000 0xffa80000 0x84 0xffa80000 0x10000 0xffa90000 0x85 0xffa90000 0x10000 0xffaa0000 0x86 0xffaa0000 0x10000 0xffab0000 0x87 0xffab0000 0x10000 0xffac0000 0x88 0xffac0000 0x10000 0xffad0000 0x89 0xffad0000 0x10000 0xffae0000 0x8a 0xffae0000 0x10000 0xffaf0000 0x8b 0xffaf0000 0x10000 0xffc90000 0x8c 0xffc90000 0xf000 0x0 0xa2 0x0 0x40000 0xf9000000 0xa4 0xf9000000 0x3000 0xffe40000 0xa5 0xffe40000 0x10000 0xffe50000 0xa6 0xffe50000 0x10000 0xffec0000 0xa7 0xffec0000 0x10000 0xffed0000 0xa8 0xffed0000 0x10000 0x0 0xaa 0x0 0x10000 0x20000 0xab 0x20000 0x10000>;
};

